# STM32MP21_CM33 register map
File version: 0.4
CPU: CM33 r0p1, little endian, MPU, FPU, vendor SysTick, 8 interrupt priority bits
Registers are 32-bit, read-write, reset 0x0 unless marked. A register's access mark holds for its fields unless they carry their own. Offsets are from the block's base; [hi:lo] are bit positions; {n}, {i} and the like mark numbered series; 'fields as' and 'values as' point back to an identical list.

## IPCC — IPCC address block description
Base 0x40490000
Same registers: IPCC_S 0x50490000
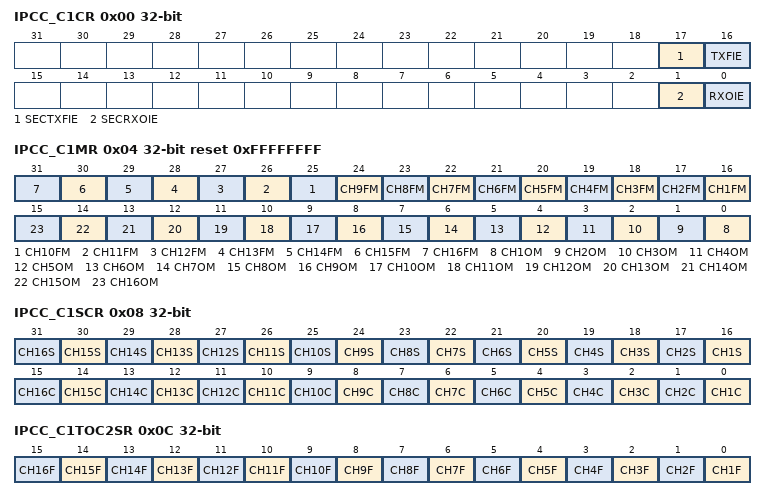
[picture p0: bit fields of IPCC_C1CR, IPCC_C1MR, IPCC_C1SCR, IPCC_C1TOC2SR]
0x00 IPCC_C1CR — IPCC processor 1 control register
  [17] SECTXFIE — Processor 1 transmit channel free secure interrupt enable.
    1=Enable an unmasked processor 1 transmit channel free to generate a TX free secure interrupt; 0=Processor 1 TX free secure interrupt disabled
  [16] TXFIE — Processor 1 transmit channel free non-secure interrupt enable
    1=Enable an unmasked processor 1 transmit channel free to generate a non-secure TX free interrupt; 0=Processor 1 non-secure TX free interrupt disabled
  [1] SECRXOIE — Processor 1 receive channel occupied secure interrupt enable.
    1=Enable an unmasked processor 1 receive channel occupied to generate an RX occupied secure interrupt; 0=Processor 1 RX occupied secure interrupt disabled
  [0] RXOIE — Processor 1 receive channel occupied interrupt enable
    1=Enable an unmasked processor 1 receive channel occupied to generate an RX occupied interrupt; 0=Processor 1 RX occupied interrupt disabled
0x04 IPCC_C1MR reset 0xFFFFFFFF — IPCC processor 1 mask register
  [n+15] CH{n}FM (n=1..16) — Processor 1 transmit channel n status set, (n = 16 to 1).
    1=Transmit channel n free interrupt masked; 0=Transmit channel n free interrupt not masked
  [n-1] CH{n}OM (n=1..16) — Processor 1 receive channel n status clear (n = 16 to 1).
    1=Receive channel n occupied interrupt masked; 0=Receive channel n occupied interrupt not masked
0x08 IPCC_C1SCR — IPCC processor 1 status set clear register
  [n+15] CH{n}S (n=1..16) — Processor 1 transmit channel n status set (n = 16 to 1).
    1=Processor 1 transmit channel n status bit set; 0=No action
  [n-1] CH{n}C (n=1..16) — Processor 1 receive channel n status clear (n = 16 to 1).
    1=Processor 1 receive channel n status bit clear; 0=No action
0x0C IPCC_C1TOC2SR ro — IPCC processor 1 to processor 2 status register
  [all] fields
    1=Channel occupied, data can be read by the receiving processor 2; 0=Channel free, data can be written by the sending processor 1
  [n-1] CH{n}F (n=1..16) — Processor 1 transmit to processor 2 receive channel n status flag before masking (n=16 to 1).
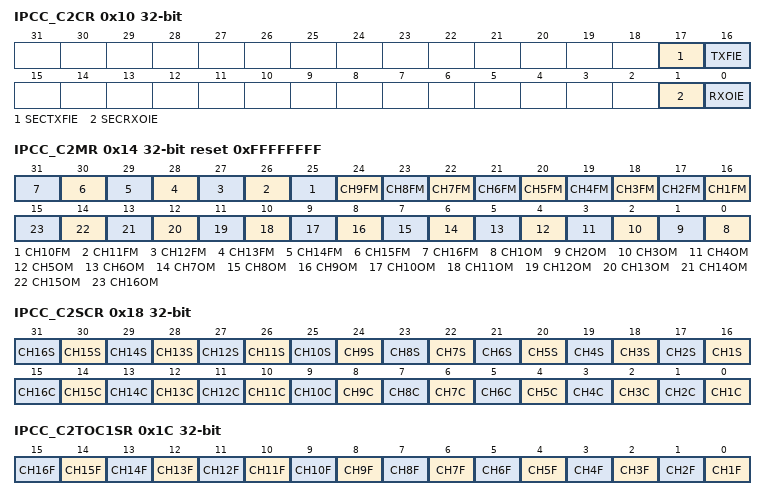
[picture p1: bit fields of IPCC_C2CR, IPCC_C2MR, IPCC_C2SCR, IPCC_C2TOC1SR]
0x10 IPCC_C2CR — IPCC processor 2 control register
  [17] SECTXFIE — Processor 2 secure transmit channel free interrupt enable.
    1=Enable an unmasked processor 2 transmit channel free to generate a secure TX free interrupt; 0=Processor 2 secure TX free interrupt disabled
  [16] TXFIE — Processor 2 transmit channel free interrupt enable
    1=Enable an unmasked processor 2 transmit channel free to generate a TX free interrupt; 0=Processor 2 TX free interrupt disabled
  [1] SECRXOIE — Processor 2 secure Receive channel occupied interrupt enable.
    1=Enable an unmasked processor 2 receive channel occupied to generate an secure RX occupied interrupt; 0=Processor 2 secure RX occupied interrupt disabled
  [0] RXOIE — Processor 2 receive channel occupied interrupt enable
    1=Enable an unmasked processor 2 receive channel occupied to generate an RX occupied interrupt; 0=Processor 2 RX occupied interrupt disabled
0x14 IPCC_C2MR reset 0xFFFFFFFF — IPCC processor 2 mask register
  [n+15] CH{n}FM (n=1..16) — Processor 2 transmit channel n free interrupt mask (n = 16 to 1).
    values as IPCC_C1MR.CH1FM
  [n-1] CH{n}OM (n=1..16) — Processor 2 receive channel n occupied interrupt mask (n = 16 to 1).
    values as IPCC_C1MR.CH1OM
0x18 IPCC_C2SCR — IPCC processor 2 status set clear register
  [n+15] CH{n}S (n=1..16) — Processor 2 transmit channel n status set (n = 16 to 1).
    1=Processor 2 transmit channel n status bit set; 0=No action
  [n-1] CH{n}C (n=1..16) — Processor 2 receive channel n status clear (n = 16 to 1).
    1=Processor 2 receive channel n status bit clear; 0=No action
0x1C IPCC_C2TOC1SR ro — IPCC processor 2 to processor 1 status register
  [all] fields
    1=Channel occupied, data can be read by the receiving processor 1; 0=Channel free, data can be written by the sending processor 2
  [n-1] CH{n}F (n=1..16) — Processor 2 transmit to processor 1 receive channel n status flag before masking (n=16 to 1)
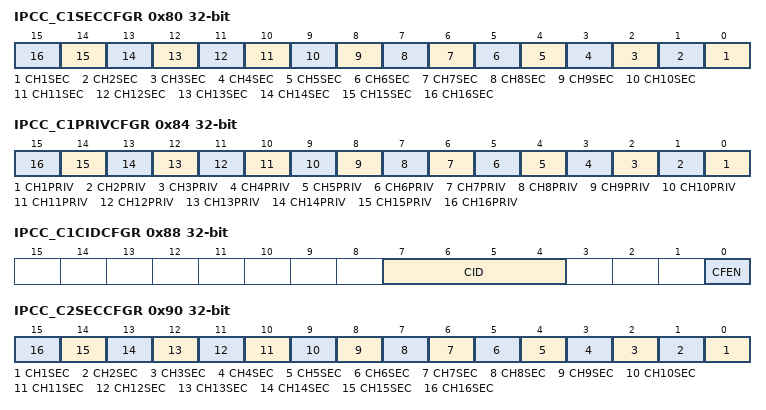
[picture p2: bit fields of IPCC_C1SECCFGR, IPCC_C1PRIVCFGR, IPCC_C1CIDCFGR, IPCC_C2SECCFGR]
0x80 IPCC_C1SECCFGR — IPCC processor 1 security configuration register
  [all] fields
    1=Channel n processor 1 security enabled (secure); 0=Channel n processor 1 security disabled (non-secure)
  [n-1] CH{n}SEC (n=1..16) — Processor 1 channel n security enable (n = 16 to 1).
0x84 IPCC_C1PRIVCFGR — IPCC processor 1 privilege configuration register
  [all] fields
    1=Channel n processor 1 privilege enabled (privileged); 0=Channel n processor 1 privilege disabled (unprivileged)
  [n-1] CH{n}PRIV (n=1..16) — Processor 1 channel n privilege enable (n = 16 to 1).
0x88 IPCC_C1CIDCFGR — IPCC processor 1 CID configuration register
  [7:4] CID — Processor 1 CID domain identification
  [0] CFEN — CID filtering enabled for processor 1
    0=disable the processor 1 CID filtering and interrupt routing, Processor 1 interrupts are broadcast to all CIDs; 1=enable the processor 1 CID filtering and interrupt routing
0x90 IPCC_C2SECCFGR — IPCC processor 2 security configuration register
  [all] fields
    1=Channel n processor 2 security enabled (secure); 0=Channel n processor 2 security disabled (non-secure)
  [n-1] CH{n}SEC (n=1..16) — Processor 2 channel n security enable
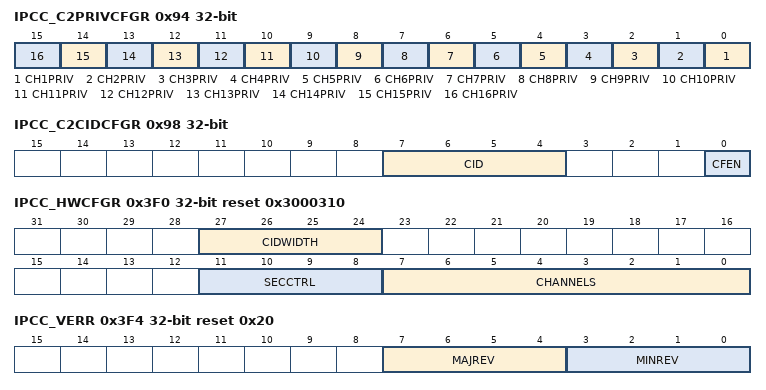
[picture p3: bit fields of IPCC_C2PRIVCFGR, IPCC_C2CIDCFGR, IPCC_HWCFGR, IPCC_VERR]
0x94 IPCC_C2PRIVCFGR — IPCC processor 2 privilege configuration register
  [all] fields
    1=Channel n processor 2 privilege enabled (privileged); 0=Channel n processor 2 privilege disabled (unprivileged)
  [n-1] CH{n}PRIV (n=1..16) — Processor 2 channel n privilege enable (n = 16 to 1).
0x98 IPCC_C2CIDCFGR — IPCC processor 2 CID configuration register
  [7:4] CID — Processor 2 CID domain identification
  [0] CFEN — CID filtering enabled for processor 2
    0=disable the processor 2 CID filtering and interrupt routing, Processor 2 interrupts are broadcast to all CIDs; 1=enable the processor 2 CID filtering and interrupt routing
0x3F0 IPCC_HWCFGR ro reset 0x3000310 — IPCC hardware configuration register
  [27:24] CIDWIDTH — CID bit field width range 0 to 12.
    0=No CID filtering
  [11:8] SECCTRL — Security options, range 1 to 16.
    0=No security; 1=Security
  [7:0] CHANNELS — Number of channels per CPU supported by the IP, range 1 to 16
0x3F4 IPCC_VERR ro reset 0x20 — IPCC version register
  [7:4] MAJREV — IPCC major revision number
  [3:0] MINREV — IPCC minor revision number.
0x3F8 IPCC_IPIDR ro reset 0x100071 — IPCC identification register
  [31:0] IPID — IPCC identification.
0x3FC IPCC_SIDR ro reset 0xA3C5DD01 — IPCC size identification register
  [31:0] SID — IPCC size identification.
